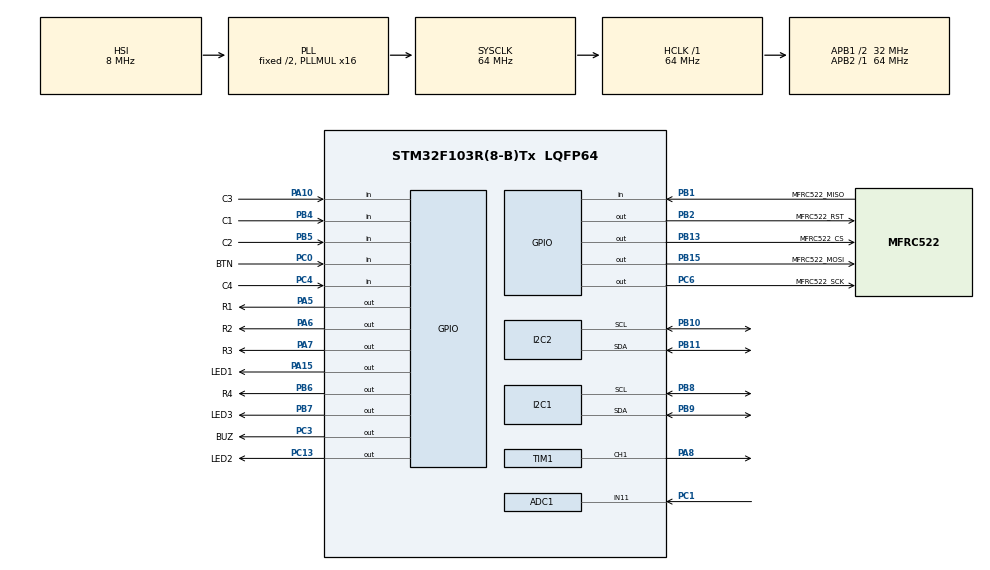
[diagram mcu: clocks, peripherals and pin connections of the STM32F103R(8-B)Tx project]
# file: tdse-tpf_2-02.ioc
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ADC1.Channel-2\#ChannelRegularConversion=ADC_CHANNEL_11
ADC1.NbrOfConversionFlag=1
ADC1.Rank-2\#ChannelRegularConversion=1
ADC1.SamplingTime-2\#ChannelRegularConversion=ADC_SAMPLETIME_1CYCLE_5
ADC1.master=1
I2C1.I2C_Mode=I2C_Standard
I2C2.I2C_Mode=I2C_Fast
Mcu.Family=STM32F1
Mcu.Name=STM32F103R(8-B)Tx
Mcu.Package=LQFP64
NVIC.PriorityGroup=NVIC_PRIORITYGROUP_4
PA10.GPIO_Label=C3
PA10.GPIO_PuPd=GPIO_PULLUP
PA10.Signal=GPIO_Input
PA13.GPIO_Label=TMS
PA13.Mode=Serial_Wire
PA13.Signal=SYS_JTMS-SWDIO
PA14.GPIO_Label=TCK
PA14.Mode=Serial_Wire
PA14.Signal=SYS_JTCK-SWCLK
PA15.GPIO_Label=LED1
PA15.Signal=GPIO_Output
PA5.GPIO_Label=R1
PA5.Signal=GPIO_Output
PA6.GPIO_Label=R2
PA6.Signal=GPIO_Output
PA7.GPIO_Label=R3
PA7.Signal=GPIO_Output
PA8.Signal=S_TIM1_CH1
PB1.GPIO_Label=MFRC522_MISO
PB1.Signal=GPIO_Input
PB10.Mode=I2C
PB10.Signal=I2C2_SCL
PB11.Mode=I2C
PB11.Signal=I2C2_SDA
PB13.GPIO_Label=MFRC522_CS
PB13.Signal=GPIO_Output
PB15.GPIO_Label=MFRC522_MOSI
PB15.Signal=GPIO_Output
PB2.GPIO_Label=MFRC522_RST
PB2.Signal=GPIO_Output
PB3.GPIO_Label=SWO
PB3.Signal=SYS_JTDO-TRACESWO
PB4.GPIO_Label=C1
PB4.GPIO_PuPd=GPIO_PULLUP
PB4.Signal=GPIO_Input
PB5.GPIO_Label=C2
PB5.GPIO_PuPd=GPIO_PULLUP
PB5.Signal=GPIO_Input
PB6.GPIO_Label=R4
PB6.Signal=GPIO_Output
PB7.GPIO_Label=LED3
PB7.Signal=GPIO_Output
PB8.Mode=I2C
PB8.Signal=I2C1_SCL
PB9.Mode=I2C
PB9.Signal=I2C1_SDA
PC0.GPIO_Label=BTN
PC0.GPIO_PuPd=GPIO_PULLUP
PC0.Signal=GPIO_Input
PC1.Signal=ADCx_IN11
PC13-TAMPER-RTC.GPIO_Label=LED2
PC13-TAMPER-RTC.Signal=GPIO_Output
PC14-OSC32_IN.Mode=LSE-External-Oscillator
PC14-OSC32_IN.Signal=RCC_OSC32_IN
PC15-OSC32_OUT.Mode=LSE-External-Oscillator
PC15-OSC32_OUT.Signal=RCC_OSC32_OUT
PC3.GPIO_Label=BUZ
PC3.Signal=GPIO_Output
PC4.GPIO_Label=C4
PC4.GPIO_PuPd=GPIO_PULLUP
PC4.Signal=GPIO_Input
PC6.GPIO_Label=MFRC522_SCK
PC6.Signal=GPIO_Output
PD0-OSC_IN.Mode=HSE-External-Clock-Source
PD0-OSC_IN.Signal=RCC_OSC_IN
PD1-OSC_OUT.Mode=HSE-External-Clock-Source
PD1-OSC_OUT.Signal=RCC_OSC_OUT
ProjectManager.HeapSize=0x200
ProjectManager.StackSize=0x400
ProjectManager.TargetToolchain=STM32CubeIDE
RCC.ADCPresc=RCC_ADCPCLK2_DIV8
RCC.AHBFreq_Value=64000000
RCC.APB1CLKDivider=RCC_HCLK_DIV2
RCC.APB1Freq_Value=32000000
RCC.APB1TimFreq_Value=64000000
RCC.APB2Freq_Value=64000000
RCC.APB2TimFreq_Value=64000000
RCC.HCLKFreq_Value=64000000
RCC.PLLMUL=RCC_PLL_MUL16
RCC.RTCClockSelection=RCC_RTCCLKSOURCE_LSE
RCC.SYSCLKFreq_VALUE=64000000
RCC.SYSCLKSource=RCC_SYSCLKSOURCE_PLLCLK
RCC.USBFreq_Value=64000000
SH.ADCx_IN11.0=ADC1_IN11,IN11
SH.S_TIM1_CH1.0=TIM1_CH1,PWM Generation1 CH1
TIM1.Channel-PWM\ Generation1\ CH1=TIM_CHANNEL_1
TIM1.Period=19999
TIM1.Prescaler=63
board=NUCLEO-F103RB

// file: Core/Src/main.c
/* USER CODE BEGIN Header */
/**
  ******************************************************************************
  * @file           : main.c
  * @brief          : Main program body
  ******************************************************************************
  * @attention
  *
  * Copyright (c) 2025 STMicroelectronics.
  * All rights reserved.
  *
  * This software is licensed under terms that can be found in the LICENSE file
  * in the root directory of this software component.
  * If no LICENSE file comes with this software, it is provided AS-IS.
  *
  ******************************************************************************
  */
/* USER CODE END Header */
#include "main.h"

/* USER CODE BEGIN Includes */

/* Demo includes. */
#include "logger.h"
#include "dwt.h"

/* Application includes. */
#include "app.h"

/* USER CODE END Includes */

ADC_HandleTypeDef hadc1;

I2C_HandleTypeDef hi2c1;
I2C_HandleTypeDef hi2c2;

TIM_HandleTypeDef htim1;

void SystemClock_Config(void);
static void MX_GPIO_Init(void);
static void MX_I2C1_Init(void);
static void MX_TIM1_Init(void);
static void MX_ADC1_Init(void);
static void MX_I2C2_Init(void);

/* USER CODE BEGIN 0 */
extern void initialise_monitor_handles(void);

/* USER CODE END 0 */

int main(void)
{

  /* USER CODE BEGIN 1 */
	#if LOGGER_CONFIG_ENABLE
		initialise_monitor_handles();
	#endif

  /* USER CODE END 1 */

  /* MCU Configuration--------------------------------------------------------*/

  /* Reset of all peripherals, Initializes the Flash interface and the Systick. */
  HAL_Init();

  /* Configure the system clock */
  SystemClock_Config();

  /* Initialize all configured peripherals */
  MX_GPIO_Init();
  MX_I2C1_Init();
  MX_TIM1_Init();
  MX_ADC1_Init();
  MX_I2C2_Init();
  /* USER CODE BEGIN 2 */

	/* Application Init */
	app_init();

  /* USER CODE END 2 */

  /* Infinite loop */
  while (1)
  {

    /* USER CODE BEGIN 3 */
	  /* Application Update */
	  app_update();

  }
  /* USER CODE END 3 */
}

void SystemClock_Config(void)
{
  RCC_OscInitTypeDef RCC_OscInitStruct = {0};
  RCC_ClkInitTypeDef RCC_ClkInitStruct = {0};
  RCC_PeriphCLKInitTypeDef PeriphClkInit = {0};

  /** Initializes the RCC Oscillators according to the specified parameters
  * in the RCC_OscInitTypeDef structure.
  */
  RCC_OscInitStruct.OscillatorType = RCC_OSCILLATORTYPE_HSI;
  RCC_OscInitStruct.HSIState = RCC_HSI_ON;
  RCC_OscInitStruct.HSICalibrationValue = RCC_HSICALIBRATION_DEFAULT;
  RCC_OscInitStruct.PLL.PLLState = RCC_PLL_ON;
  RCC_OscInitStruct.PLL.PLLSource = RCC_PLLSOURCE_HSI_DIV2;
  RCC_OscInitStruct.PLL.PLLMUL = RCC_PLL_MUL16;
  if (HAL_RCC_OscConfig(&RCC_OscInitStruct) != HAL_OK)
  {
    Error_Handler();
  }

  /** Initializes the CPU, AHB and APB buses clocks
  */
  RCC_ClkInitStruct.ClockType = RCC_CLOCKTYPE_HCLK|RCC_CLOCKTYPE_SYSCLK
                              |RCC_CLOCKTYPE_PCLK1|RCC_CLOCKTYPE_PCLK2;
  RCC_ClkInitStruct.SYSCLKSource = RCC_SYSCLKSOURCE_PLLCLK;
  RCC_ClkInitStruct.AHBCLKDivider = RCC_SYSCLK_DIV1;
  RCC_ClkInitStruct.APB1CLKDivider = RCC_HCLK_DIV2;
  RCC_ClkInitStruct.APB2CLKDivider = RCC_HCLK_DIV1;

  if (HAL_RCC_ClockConfig(&RCC_ClkInitStruct, FLASH_LATENCY_2) != HAL_OK)
  {
    Error_Handler();
  }
  PeriphClkInit.PeriphClockSelection = RCC_PERIPHCLK_ADC;
  PeriphClkInit.AdcClockSelection = RCC_ADCPCLK2_DIV8;
  if (HAL_RCCEx_PeriphCLKConfig(&PeriphClkInit) != HAL_OK)
  {
    Error_Handler();
  }
}

static void MX_ADC1_Init(void)
{

  ADC_ChannelConfTypeDef sConfig = {0};

  /** Common config
  */
  hadc1.Instance = ADC1;
  hadc1.Init.ScanConvMode = ADC_SCAN_DISABLE;
  hadc1.Init.ContinuousConvMode = DISABLE;
  hadc1.Init.DiscontinuousConvMode = DISABLE;
  hadc1.Init.ExternalTrigConv = ADC_SOFTWARE_START;
  hadc1.Init.DataAlign = ADC_DATAALIGN_RIGHT;
  hadc1.Init.NbrOfConversion = 1;
  if (HAL_ADC_Init(&hadc1) != HAL_OK)
  {
    Error_Handler();
  }

  /** Configure Regular Channel
  */
  sConfig.Channel = ADC_CHANNEL_11;
  sConfig.Rank = ADC_REGULAR_RANK_1;
  sConfig.SamplingTime = ADC_SAMPLETIME_1CYCLE_5;
  if (HAL_ADC_ConfigChannel(&hadc1, &sConfig) != HAL_OK)
  {
    Error_Handler();
  }

}

static void MX_I2C1_Init(void)
{

  hi2c1.Instance = I2C1;
  hi2c1.Init.ClockSpeed = 100000;
  hi2c1.Init.DutyCycle = I2C_DUTYCYCLE_2;
  hi2c1.Init.OwnAddress1 = 0;
  hi2c1.Init.AddressingMode = I2C_ADDRESSINGMODE_7BIT;
  hi2c1.Init.DualAddressMode = I2C_DUALADDRESS_DISABLE;
  hi2c1.Init.OwnAddress2 = 0;
  hi2c1.Init.GeneralCallMode = I2C_GENERALCALL_DISABLE;
  hi2c1.Init.NoStretchMode = I2C_NOSTRETCH_DISABLE;
  if (HAL_I2C_Init(&hi2c1) != HAL_OK)
  {
    Error_Handler();
  }

}

static void MX_I2C2_Init(void)
{

  hi2c2.Instance = I2C2;
  hi2c2.Init.ClockSpeed = 400000;
  hi2c2.Init.DutyCycle = I2C_DUTYCYCLE_2;
  hi2c2.Init.OwnAddress1 = 0;
  hi2c2.Init.AddressingMode = I2C_ADDRESSINGMODE_7BIT;
  hi2c2.Init.DualAddressMode = I2C_DUALADDRESS_DISABLE;
  hi2c2.Init.OwnAddress2 = 0;
  hi2c2.Init.GeneralCallMode = I2C_GENERALCALL_DISABLE;
  hi2c2.Init.NoStretchMode = I2C_NOSTRETCH_DISABLE;
  if (HAL_I2C_Init(&hi2c2) != HAL_OK)
  {
    Error_Handler();
  }

}

static void MX_TIM1_Init(void)
{

  TIM_MasterConfigTypeDef sMasterConfig = {0};
  TIM_OC_InitTypeDef sConfigOC = {0};
  TIM_BreakDeadTimeConfigTypeDef sBreakDeadTimeConfig = {0};

  htim1.Instance = TIM1;
  htim1.Init.Prescaler = 63;
  htim1.Init.CounterMode = TIM_COUNTERMODE_UP;
  htim1.Init.Period = 19999;
  htim1.Init.ClockDivision = TIM_CLOCKDIVISION_DIV1;
  htim1.Init.RepetitionCounter = 0;
  htim1.Init.AutoReloadPreload = TIM_AUTORELOAD_PRELOAD_DISABLE;
  if (HAL_TIM_PWM_Init(&htim1) != HAL_OK)
  {
    Error_Handler();
  }
  sMasterConfig.MasterOutputTrigger = TIM_TRGO_RESET;
  sMasterConfig.MasterSlaveMode = TIM_MASTERSLAVEMODE_DISABLE;
  if (HAL_TIMEx_MasterConfigSynchronization(&htim1, &sMasterConfig) != HAL_OK)
  {
    Error_Handler();
  }
  sConfigOC.OCMode = TIM_OCMODE_PWM1;
  sConfigOC.Pulse = 0;
  sConfigOC.OCPolarity = TIM_OCPOLARITY_HIGH;
  sConfigOC.OCNPolarity = TIM_OCNPOLARITY_HIGH;
  sConfigOC.OCFastMode = TIM_OCFAST_DISABLE;
  sConfigOC.OCIdleState = TIM_OCIDLESTATE_RESET;
  sConfigOC.OCNIdleState = TIM_OCNIDLESTATE_RESET;
  if (HAL_TIM_PWM_ConfigChannel(&htim1, &sConfigOC, TIM_CHANNEL_1) != HAL_OK)
  {
    Error_Handler();
  }
  sBreakDeadTimeConfig.OffStateRunMode = TIM_OSSR_DISABLE;
  sBreakDeadTimeConfig.OffStateIDLEMode = TIM_OSSI_DISABLE;
  sBreakDeadTimeConfig.LockLevel = TIM_LOCKLEVEL_OFF;
  sBreakDeadTimeConfig.DeadTime = 0;
  sBreakDeadTimeConfig.BreakState = TIM_BREAK_DISABLE;
  sBreakDeadTimeConfig.BreakPolarity = TIM_BREAKPOLARITY_HIGH;
  sBreakDeadTimeConfig.AutomaticOutput = TIM_AUTOMATICOUTPUT_DISABLE;
  if (HAL_TIMEx_ConfigBreakDeadTime(&htim1, &sBreakDeadTimeConfig) != HAL_OK)
  {
    Error_Handler();
  }
  HAL_TIM_MspPostInit(&htim1);

}

static void MX_GPIO_Init(void)
{
  GPIO_InitTypeDef GPIO_InitStruct = {0};

  /* GPIO Ports Clock Enable */
  __HAL_RCC_GPIOC_CLK_ENABLE();
  __HAL_RCC_GPIOD_CLK_ENABLE();
  __HAL_RCC_GPIOA_CLK_ENABLE();
  __HAL_RCC_GPIOB_CLK_ENABLE();

  /*Configure GPIO pin Output Level */
  HAL_GPIO_WritePin(GPIOC, LED2_Pin|BUZ_Pin|MFRC522_SCK_Pin, GPIO_PIN_RESET);

  /*Configure GPIO pin Output Level */
  HAL_GPIO_WritePin(GPIOA, R1_Pin|R2_Pin|R3_Pin|LED1_Pin, GPIO_PIN_RESET);

  /*Configure GPIO pin Output Level */
  HAL_GPIO_WritePin(GPIOB, MFRC522_RST_Pin|MFRC522_CS_Pin|MFRC522_MOSI_Pin|R4_Pin
                          |LED3_Pin, GPIO_PIN_RESET);

  /*Configure GPIO pins : LED2_Pin BUZ_Pin MFRC522_SCK_Pin */
  GPIO_InitStruct.Pin = LED2_Pin|BUZ_Pin|MFRC522_SCK_Pin;
  GPIO_InitStruct.Mode = GPIO_MODE_OUTPUT_PP;
  GPIO_InitStruct.Pull = GPIO_NOPULL;
  GPIO_InitStruct.Speed = GPIO_SPEED_FREQ_LOW;
  HAL_GPIO_Init(GPIOC, &GPIO_InitStruct);

  /*Configure GPIO pins : BTN_Pin C4_Pin */
  GPIO_InitStruct.Pin = BTN_Pin|C4_Pin;
  GPIO_InitStruct.Mode = GPIO_MODE_INPUT;
  GPIO_InitStruct.Pull = GPIO_PULLUP;
  HAL_GPIO_Init(GPIOC, &GPIO_InitStruct);

  /*Configure GPIO pins : R1_Pin R2_Pin R3_Pin LED1_Pin */
  GPIO_InitStruct.Pin = R1_Pin|R2_Pin|R3_Pin|LED1_Pin;
  GPIO_InitStruct.Mode = GPIO_MODE_OUTPUT_PP;
  GPIO_InitStruct.Pull = GPIO_NOPULL;
  GPIO_InitStruct.Speed = GPIO_SPEED_FREQ_LOW;
  HAL_GPIO_Init(GPIOA, &GPIO_InitStruct);

  /*Configure GPIO pin : MFRC522_MISO_Pin */
  GPIO_InitStruct.Pin = MFRC522_MISO_Pin;
  GPIO_InitStruct.Mode = GPIO_MODE_INPUT;
  GPIO_InitStruct.Pull = GPIO_NOPULL;
  HAL_GPIO_Init(MFRC522_MISO_GPIO_Port, &GPIO_InitStruct);

  /*Configure GPIO pins : MFRC522_RST_Pin MFRC522_CS_Pin MFRC522_MOSI_Pin R4_Pin
                           LED3_Pin */
  GPIO_InitStruct.Pin = MFRC522_RST_Pin|MFRC522_CS_Pin|MFRC522_MOSI_Pin|R4_Pin
                          |LED3_Pin;
  GPIO_InitStruct.Mode = GPIO_MODE_OUTPUT_PP;
  GPIO_InitStruct.Pull = GPIO_NOPULL;
  GPIO_InitStruct.Speed = GPIO_SPEED_FREQ_LOW;
  HAL_GPIO_Init(GPIOB, &GPIO_InitStruct);

  /*Configure GPIO pin : C3_Pin */
  GPIO_InitStruct.Pin = C3_Pin;
  GPIO_InitStruct.Mode = GPIO_MODE_INPUT;
  GPIO_InitStruct.Pull = GPIO_PULLUP;
  HAL_GPIO_Init(C3_GPIO_Port, &GPIO_InitStruct);

  /*Configure GPIO pins : C1_Pin C2_Pin */
  GPIO_InitStruct.Pin = C1_Pin|C2_Pin;
  GPIO_InitStruct.Mode = GPIO_MODE_INPUT;
  GPIO_InitStruct.Pull = GPIO_PULLUP;
  HAL_GPIO_Init(GPIOB, &GPIO_InitStruct);

}

void Error_Handler(void)
{
  __disable_irq();
  while (1)
  {
  }
}
